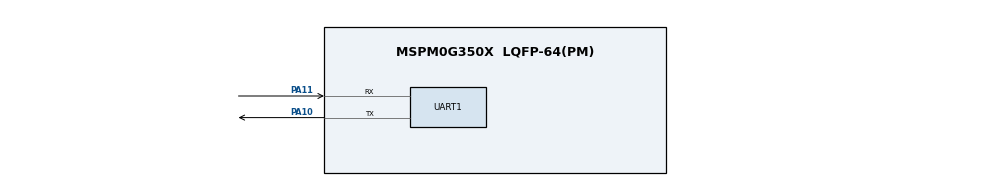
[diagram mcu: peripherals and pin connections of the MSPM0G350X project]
/**
 * @cliArgs --device "MSPM0G350X" --part "Default" --package "LQFP-64(PM)" --product "mspm0_sdk@2.05.01.01"
 * @versions {"tool":"1.24.0+4110"}
 */

/**
 * Import the modules used in this configuration.
 */
const GPIO   = scripting.addModule("/ti/driverlib/GPIO", {}, false);
const GPIO1  = GPIO.addInstance();
const GPIO2  = GPIO.addInstance();
const GPIO3  = GPIO.addInstance();
const SYSCTL = scripting.addModule("/ti/driverlib/SYSCTL");
const TIMER  = scripting.addModule("/ti/driverlib/TIMER", {}, false);
const TIMER1 = TIMER.addInstance();
const UART   = scripting.addModule("/ti/driverlib/UART", {}, false);
const UART1  = UART.addInstance();

/**
 * Write custom configuration values to the imported modules.
 */
const divider9       = system.clockTree["UDIV"];
divider9.divideValue = 2;

const multiplier2         = system.clockTree["PLL_QDIV"];
multiplier2.multiplyValue = 4;

const mux4       = system.clockTree["EXHFMUX"];
mux4.inputSelect = "EXHFMUX_XTAL";

const mux8       = system.clockTree["HSCLKMUX"];
mux8.inputSelect = "HSCLKMUX_SYSPLL0";

const mux12       = system.clockTree["SYSPLLMUX"];
mux12.inputSelect = "zSYSPLLMUX_HFCLK";

const pinFunction4        = system.clockTree["HFXT"];
pinFunction4.inputFreq    = 40;
pinFunction4.enable       = true;
pinFunction4.HFXTStartup  = 10;
pinFunction4.HFCLKMonitor = true;

GPIO1.$name                              = "DEBUG_LED";
GPIO1.associatedPins[0].$name            = "PIN_22";
GPIO1.associatedPins[0].internalResistor = "PULL_DOWN";
GPIO1.associatedPins[0].assignedPort     = "PORTB";
GPIO1.associatedPins[0].assignedPin      = "22";

const Board = scripting.addModule("/ti/driverlib/Board", {}, false);

GPIO2.$name                          = "OLED";
GPIO2.associatedPins.create(2);
GPIO2.associatedPins[0].$name        = "SDA";
GPIO2.associatedPins[0].initialValue = "SET";
GPIO2.associatedPins[0].assignedPort = "PORTB";
GPIO2.associatedPins[0].assignedPin  = "8";
GPIO2.associatedPins[1].$name        = "SCL";
GPIO2.associatedPins[1].initialValue = "SET";
GPIO2.associatedPins[1].assignedPort = "PORTB";
GPIO2.associatedPins[1].assignedPin  = "9";

GPIO3.$name                              = "KEY";
GPIO3.associatedPins.create(4);
GPIO3.associatedPins[0].$name            = "ENTER";
GPIO3.associatedPins[0].direction        = "INPUT";
GPIO3.associatedPins[0].internalResistor = "PULL_UP";
GPIO3.associatedPins[0].assignedPort     = "PORTB";
GPIO3.associatedPins[0].assignedPin      = "21";
GPIO3.associatedPins[1].$name            = "BACK";
GPIO3.associatedPins[1].direction        = "INPUT";
GPIO3.associatedPins[1].internalResistor = "PULL_DOWN";
GPIO3.associatedPins[1].assignedPort     = "PORTA";
GPIO3.associatedPins[1].assignedPin      = "18";
GPIO3.associatedPins[2].$name            = "UP";
GPIO3.associatedPins[2].direction        = "INPUT";
GPIO3.associatedPins[2].internalResistor = "PULL_UP";
GPIO3.associatedPins[3].$name            = "DOWN";
GPIO3.associatedPins[3].direction        = "INPUT";

SYSCTL.forceDefaultClkConfig = true;
SYSCTL.clockTreeEn           = true;
scripting.suppress("For best practices when the CPUCLK is running at 32MHz and above, clear the flash status bit using DL_FlashCTL_executeClearStatus\\(\\) before executing any flash operation\\. Otherwise there may be false positives\\.", SYSCTL);

TIMER1.timerClkDiv       = 8;
TIMER1.timerClkPrescale  = 10;
TIMER1.timerStartTimer   = true;
TIMER1.timerMode         = "PERIODIC";
TIMER1.interrupts        = ["ZERO"];
TIMER1.interruptPriority = "3";
TIMER1.$name             = "TIMER_TICK";
TIMER1.timerPeriod       = "50 ms";

UART1.enabledInterrupts                = ["RX"];
UART1.interruptPriority                = "3";
UART1.$name                            = "UART_DEBUG";
UART1.peripheral.rxPin.$assign         = "PA11";
UART1.peripheral.txPin.$assign         = "PA10";
UART1.txPinConfig.$name                = "ti_driverlib_gpio_GPIOPinGeneric0";
UART1.txPinConfig.direction            = scripting.forceWrite("OUTPUT");
UART1.txPinConfig.hideOutputInversion  = scripting.forceWrite(false);
UART1.txPinConfig.onlyInternalResistor = scripting.forceWrite(false);
UART1.txPinConfig.passedPeripheralType = scripting.forceWrite("Digital");
UART1.rxPinConfig.$name                = "ti_driverlib_gpio_GPIOPinGeneric1";
UART1.rxPinConfig.hideOutputInversion  = scripting.forceWrite(false);
UART1.rxPinConfig.onlyInternalResistor = scripting.forceWrite(false);
UART1.rxPinConfig.passedPeripheralType = scripting.forceWrite("Digital");

/**
 * Pinmux solution for unlocked pins/peripherals. This ensures that minor changes to the automatic solver in a future
 * version of the tool will not impact the pinmux you originally saw.  These lines can be completely deleted in order to
 * re-solve from scratch.
 */
pinFunction4.peripheral.$suggestSolution           = "SYSCTL";
pinFunction4.peripheral.hfxInPin.$suggestSolution  = "PA5";
pinFunction4.peripheral.hfxOutPin.$suggestSolution = "PA6";
GPIO1.associatedPins[0].pin.$suggestSolution       = "PB22";
Board.peripheral.$suggestSolution                  = "DEBUGSS";
Board.peripheral.swclkPin.$suggestSolution         = "PA20";
Board.peripheral.swdioPin.$suggestSolution         = "PA19";
GPIO2.associatedPins[0].pin.$suggestSolution       = "PB8";
GPIO2.associatedPins[1].pin.$suggestSolution       = "PB9";
GPIO3.associatedPins[0].pin.$suggestSolution       = "PB21";
GPIO3.associatedPins[1].pin.$suggestSolution       = "PA18";
GPIO3.associatedPins[2].pin.$suggestSolution       = "PB13";
GPIO3.associatedPins[3].pin.$suggestSolution       = "PB14";
TIMER1.peripheral.$suggestSolution                 = "TIMA0";
UART1.peripheral.$suggestSolution                  = "UART0";
